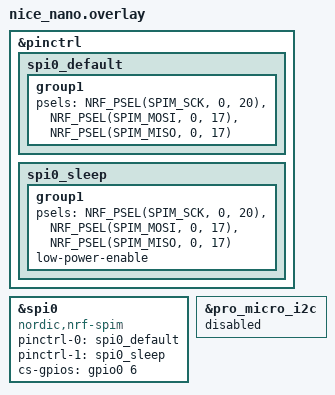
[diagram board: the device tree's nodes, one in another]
/*
 * Override nice_view_adapter wiring for nice!nano + nice!view.
 *
 * nice!view default wiring (nice!nano):
 * - CS   = D1  = P0.06
 * - SCK  = D2  = P0.20
 * - MOSI = D3  = P0.17
 *
 * Note: nice!view is effectively 3‑wire SPI (no separate MISO). We still set a
 * MISO PSEL to MOSI to satisfy SPIM pinctrl expectations.
 */

&pinctrl {
    spi0_default: spi0_default {
        group1 {
            psels = <NRF_PSEL(SPIM_SCK, 0, 20)>,
                <NRF_PSEL(SPIM_MOSI, 0, 17)>,
                <NRF_PSEL(SPIM_MISO, 0, 17)>;
        };
    };
    spi0_sleep: spi0_sleep {
        group1 {
            psels = <NRF_PSEL(SPIM_SCK, 0, 20)>,
                <NRF_PSEL(SPIM_MOSI, 0, 17)>,
                <NRF_PSEL(SPIM_MISO, 0, 17)>;
            low-power-enable;
        };
    };
};

nice_view_spi: &spi0 {
    status = "okay";
    compatible = "nordic,nrf-spim";
    pinctrl-0 = <&spi0_default>;
    pinctrl-1 = <&spi0_sleep>;
    pinctrl-names = "default", "sleep";
    cs-gpios = <&gpio0 6 GPIO_ACTIVE_HIGH>;
};

&pro_micro_i2c {
    status = "disabled";
};

